# BE-U1000 register map
Vendor: BAIKAL ELECTRONICS, JSC; File version: 1.0
CPU: RISC-V r0p0, little endian, no MPU, no FPU, 3 interrupt priority bits
Registers are 32-bit, read-write, reset 0x0 unless marked. A register's access mark holds for its fields unless they carry their own. Offsets are from the block's base; [hi:lo] are bit positions; {n}, {i} and the like mark numbered series; 'fields as' and 'values as' point back to an identical list; <NAME> marks a mode.

## USB
Base 0x15000000
0x00 FADDR 8-bit — Function address register
  [6:0] FUNC — The function address
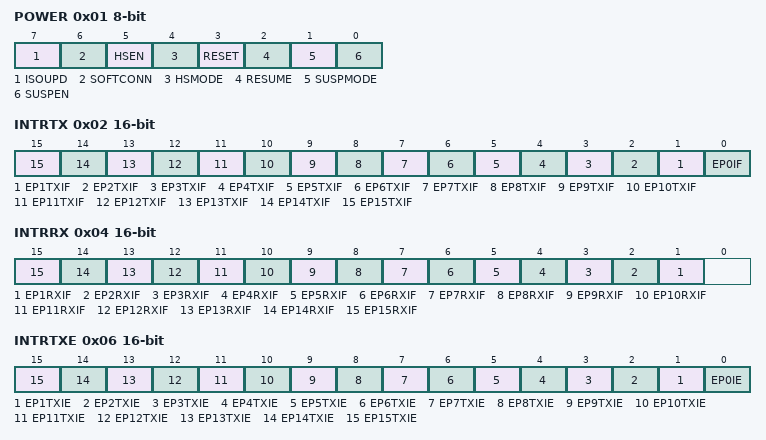
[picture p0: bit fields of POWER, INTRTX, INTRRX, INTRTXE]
0x01 POWER 8-bit — Power management register
  [all] fields
    0=DISABLE; 1=ENABLE
  [7] ISOUPD — ISO Update
  [6] SOFTCONN — Soft Connect/Disconnect feature selection
  [5] HSEN — High-speed mode control
  [4] HSMODE — High-speed mode status
  [3] RESET — Reset status
  [2] RESUME — Resume from Suspend control
  [1] SUSPMODE — Suspend mode status
  [0] SUSPEN — Suspend mode enable
0x02 INTRTX 16-bit — Interrupt register for EP 0 plus EPs 1 to 15
  [all] fields
    0=DISABLE; 1=ENABLE
  [n] EP{n}TXIF (n=1..15) — Endpoint {n} TX Interrupt Flag
  [0] EP0IF — Endpoint 0 Interrupt Flag
0x04 INTRRX 16-bit — Interrupt register for Rx EPs 1 to 15
  [all] fields
    0=DISABLE; 1=ENABLE
  [n] EP{n}RXIF (n=1..15) — Endpoint {n} RX Interrupt Flag
0x06 INTRTXE 16-bit — Interrupt enable register for IntrTx
  [all] fields
    0=DISABLE; 1=ENABLE
  [n] EP{n}TXIE (n=1..15) — Endpoint {n} TX Interrupt Enable
  [0] EP0IE — Endpoint 0 Interrupt Enable
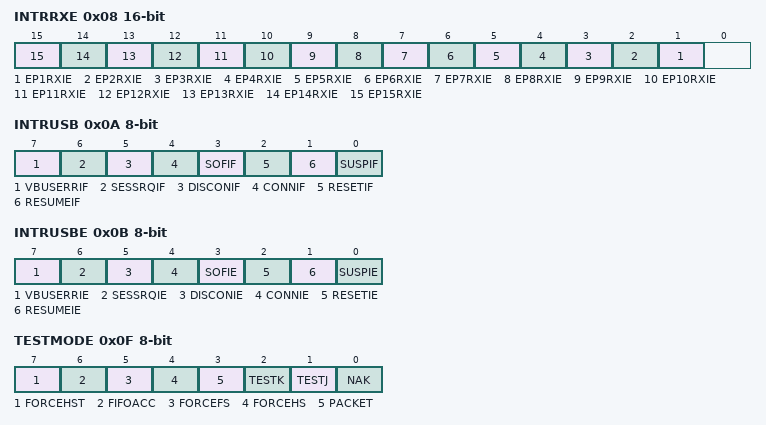
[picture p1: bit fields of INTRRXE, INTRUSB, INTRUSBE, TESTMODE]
0x08 INTRRXE 16-bit — Interrupt enable register for IntrRx
  [all] fields
    0=DISABLE; 1=ENABLE
  [n] EP{n}RXIE (n=1..15) — Endpoint {n} RX Interrupt Enable
0x0A INTRUSB 8-bit — Interrupt register for common USB interrupts
  [all] fields
    0=DISABLE; 1=ENABLE
  [7] VBUSERRIF — VBUS Error Interrupt Flag
  [6] SESSRQIF — Session Request Interrupt Flag
  [5] DISCONIF — Device Disconnect Interrupt Flag
  [4] CONNIF — Device Connection Interrupt Flag
  [3] SOFIF — Start of Frame Interrupt Flag
  [2] RESETIF — Reset/Babble Interrupt Flag
  [1] RESUMEIF — Resume Interrupt Flag
  [0] SUSPIF — Suspend Interrupt Flag
0x0B INTRUSBE 8-bit — Interrupt enable register for IntrUSB
  [all] fields
    0=DISABLE; 1=ENABLE
  [7] VBUSERRIE — VBUS Error Interrupt Enable
  [6] SESSRQIE — Session Request Interrupt Enable
  [5] DISCONIE — Device Disconnect Interrupt Enable
  [4] CONNIE — Device Connection Interrupt Enable
  [3] SOFIE — Start of Frame Interrupt Enable
  [2] RESETIE — Reset/Babble Interrupt Enable
  [1] RESUMEIE — Resume Interrupt Enable
  [0] SUSPIE — Suspend Interrupt Enable
0x0C FRAME 16-bit — Frame number
  [10:0] RFRMNUM — Last received frame number
0x0E INDEX 8-bit — Index register for selecting EP CSR
  [3:0] ENDPOINT — Endpoint registers select
0x0F TESTMODE 8-bit — Enables the USB2.0 test modes
  [all] fields
    0=DISABLE; 1=ENABLE
  [7] FORCEHST — Force host mode select
  [6] FIFOACC — Endpoint 0 FIFO transfer test mode select
  [5] FORCEFS — Force Full-Speed test mode select
  [4] FORCEHS — Force High-Speed test mode select
  [3] PACKET — Test_Packet test mode select
  [2] TESTK — Test_K test mode select
  [1] TESTJ — Test_J test mode select
  [0] NAK — Test_SE0_NAK test mode select
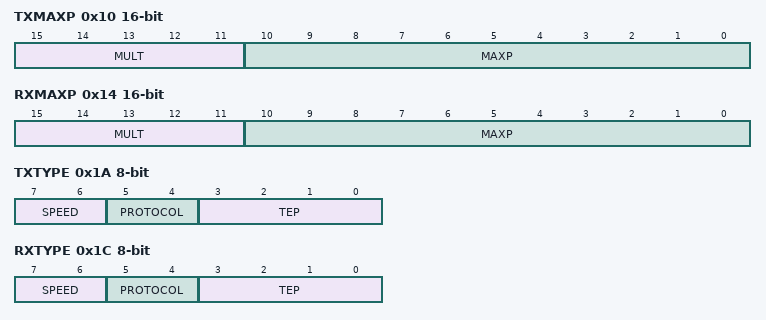
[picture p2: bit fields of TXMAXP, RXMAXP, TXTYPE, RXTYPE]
0x10 TXMAXP 16-bit — Maximum packet size for peripheral Tx EP
  [15:11] MULT — Maximum number of packets into which a single data packet should be split
  [10:0] MAXP — Maximum payload transmitted in a single transaction
0x10 TXMAXP 16-bit — Maximum packet size for host Tx EP
  fields as TXMAXP
0x12 CSR0L 8-bit — Control Status register for EP 0 Low
  [all] fields
    0=DISABLE; 1=ENABLE
  [7] PERIPH_SVSSETEND — Clear SetupEnd bit
  [7] HOST_NAKTMOUT — EP 0 is halted following NAK timeout
  [6] PERIPH_SVCRPR — Clear RxPktRdy bit
  [6] HOST_STATPKT — Perform a status stage transaction
  [5] PERIPH_SENDSTALL — Terminate current transaction
  [5] HOST_REQPKT — IN transaction request
  [4] PERIPH_SETUPEND — Control transaction ended before DataEnd bit has been set
  [4] HOST_ERROR — Three attempts to perform transaction with no response
  [3] PERIPH_DATAEND — TxPktRdy bit set / RxPktRdy bit cleared
  [3] HOST_SETUPPKT — Send SETUP token instead of OUT token
  [2] PERIPH_SENTSTALL — STALL handshake is transmitted
  [2] HOST_RXSTALL — STALL handshake is received
  [1] PERIPH_TXPKTRDY — Data packet loaded into FIFO
  [1] HOST_TXPKTRDY — Data packet loaded into FIFO
  [0] PERIPH_RXPKTRDY — Data packet received
  [0] HOST_RXPKTRDY — Data packet received
0x12 TXCSRL 8-bit — Control Status register for peripheral Tx EP Low
  [all] fields
    0=DISABLE; 1=ENABLE
  [7] PERIPH_INCOMPTX — Insufficient IN tokens for a split large packet
  [7] HOST_INCOMPTX — No response received from the device
  [6] PERIPH_CLRDT — Reset the endpoint data toggle to 0
  [6] HOST_CLRDT — Reset the endpoint data toggle to 0
  [5] PERIPH_SENTSTALL — STALL handshake is transmitted
  [5] HOST_RXSTALL — STALL handshake is received
  [4] PERIPH_SENDSTALL — Issue STALL handshake to IN token
  [4] HOST_SETUPPKT — Send SETUP token instead of OUT token
  [3] PERIPH_FLSHFIFO — Flush the latest packet from the endpoint TX FIFO
  [3] HOST_FLSHFIFO — Flush the latest packet from the endpoint TX FIFO
  [2] PERIPH_UNDERRUN — IN token received when TxPktRdy not set
  [2] HOST_ERROR — Three attempts to send a packet with no handshake received
  [1] PERIPH_FIFONE — At least 1 packet in the TX FIFO
  [1] HOST_FIFONE — At least 1 packet in the TX FIFO
  [0] PERIPH_TXPKTRDY — Data packet loaded into FIFO
  [0] HOST_TXPKTRDY — Data packet loaded into FIFO
0x12 CSR0L 8-bit — Control Status register for EP 0 Low
  fields as CSR0L
0x12 TXCSRL 8-bit — Control Status register for host Tx EP Low
  fields as TXCSRL
0x13 CSR0H 8-bit — Control Status register for EP 0 High
  [all] fields
    0=DISABLE; 1=ENABLE
  [3] HOST_DISPING — Prevent issue of PING tokens in data and status phases
  [2] HOST_DTWREN — Enable EP 0 data toggle state to be written
  [1] HOST_DATATGGL — EP 0 data toggle state
  [0] PERIPH_FLSHFIFO — Flush the next packet from the EP 0 FIFO
  [0] HOST_FLSHFIFO — Flush the next packet from the EP 0 FIFO
0x13 TXCSRH 8-bit — Control Status register for peripheral Tx EP High
  [all] fields
    0=DISABLE; 1=ENABLE
  [7] PERIPH_AUTOSET — Set TxPktRdy bit automatically
  [7] HOST_AUTOSET — Set TxPktRdy bit automatically
  [6] PERIPH_ISO — Set the endpoint transfer type
  [5] PERIPH_MODE — Set the endpoint direction
  [5] HOST_MODE — Set the endpoint direction
  [4] PERIPH_DMAREQEN — Enable the DMA request for the TX endpoint
  [4] HOST_DMAREQEN — Enable the DMA request for the TX endpoint
  [3] PERIPH_FRCDATTG — Force the endpoint data toggle to switch
  [3] HOST_FRCDATTG — Force the endpoint data toggle to switch
  [2] PERIPH_DMAREQMD — Select DMA Request Mode
  [2] HOST_DMAREQMD — Select DMA Request Mode
  [1] HOST_DTWREN — TX endpoint data toggle state write enable
  [0] HOST_DATATGGL — TX endpoint data toggle state
0x13 CSR0H 8-bit — Control Status register for EP 0 High
  fields as CSR0H
0x13 TXCSRH 8-bit — Control Status register for host Tx EP High
  fields as TXCSRH
0x14 RXMAXP 16-bit — Maximum packet size for peripheral Rx EP
  [15:11] MULT — The number of packets to be amalgamated into a single data packet
  [10:0] MAXP — Maximum payload transmitted in a single transaction
0x14 RXMAXP 16-bit — Maximum packet size for host Rx EP
  fields as RXMAXP
0x16 RXCSRL 8-bit — Control Status register for peripheral Rx EP Low
  [all] fields
    0=DISABLE; 1=ENABLE
  [7] PERIPH_CLRDT — Reset the endpoint data toggle to 0
  [7] HOST_CLRDT — Reset the endpoint data toggle to 0
  [6] PERIPH_SENTSTALL — STALL handshake is transmitted
  [6] HOST_RXSTALL — STALL handshake is received
  [5] PERIPH_SENDSTALL — Issue STALL handshake
  [5] HOST_REQPKT — IN transaction request
  [4] PERIPH_FLSHFIFO — Flush the next packet to be read from the EP RX FIFO
  [4] HOST_FLSHFIFO — Flush the next packet to be read from the EP RX FIFO
  [3] PERIPH_DATAERR — Data packet has CRC or bit-stuff error
  [3] HOST_DERRNAKT — CRC or bit-stuff error / NAK timeout
  [2] PERIPH_OVERRUN — OUT packet cannot be loaded into the RX FIFO
  [2] HOST_ERROR — No data packet has been received after three attempts
  [1] PERIPH_FIFOFULL — No more packets can be loaded into the RX FIFO
  [1] HOST_FIFOFULL — No more packets can be loaded into the RX FIFO
  [0] PERIPH_RXPKTRDY — Data packet has been received
  [0] HOST_RXPKTRDY — Data packet has been received
0x16 RXCSRL 8-bit — Control Status register for host Rx EP Low
  fields as RXCSRL
0x17 RXCSRH 8-bit — Control Status register for peripheral Rx EP High
  [all] fields
    0=DISABLE; 1=ENABLE
  [7] PERIPH_AUTOCLR — Clear RxPktRdy bit automatically
  [7] HOST_AUTOCLR — Clear RxPktRdy bit automatically
  [6] PERIPH_ISO — Set the endpoint transfer type
  [6] HOST_AUTOREQ — Set ReqPkt bit automatically
  [5] PERIPH_DMAREQEN — Enable DMA request for the RX endpoint
  [5] HOST_DMAREQEN — Enable DMA request for the RX endpoint
  [4] PERIPH_DISNYET — Disable sending of NYET handshakes
  [4] HOST_PIDERR — PID error in the received packet
  [3] PERIPH_DMAREQMD — Select DMA Request Mode
  [3] HOST_DMAREQMD — Select DMA Request Mode
  [2] HOST_DATATWEN — Enable state of the EP 0 data toggle to be written
  [1] HOST_DATATGGL — State of the EP 0 data toggle
  [0] PERIPH_INCOMPRX — The packet in RX FIFO is incomplete
  [0] HOST_INCOMPRX — The packet received is incomplete
0x17 RXCSRH 8-bit — Control Status register for host Rx EP High
  fields as RXCSRH
0x18 COUNT0 8-bit — Number of received bytes in EP 0 FIFO
  [6:0] EP0RXCNT — The number of received data bytes in the EP 0 FIFO
0x18 RXCOUNT 16-bit — Number of bytes to be read from peripheral Rx EP FIFO
  [13:0] EPRXCNT — The number of data bytes to be read from RX FIFO
0x18 COUNT0 8-bit — Number of received bytes in EP 0 FIFO
  [6:0] EP0RXCNT — The number of received data bytes in the EP 0 FIFO
0x18 RXCOUNT 16-bit — Number of bytes to be read from host Rx EP FIFO
  [13:0] EPRXCNT — The number of data bytes to be read from RX FIFO
0x1A TYPE0 8-bit — Defines the speed of EP 0
  [7:6] SPEED — The operating speed of the targeted device
0x1A TXTYPE 8-bit — Sets protocol, speed and peripheral EP number for the host Tx EP
  [7:6] SPEED — The operating speed of the target device
  [5:4] PROTOCOL — Protocol for the TX endpoint
  [3:0] TEP — EP number from the TX EP descriptor returned during enumeration
0x1B NAKLIMIT0 8-bit — Sets NAK response timeout on EP 0
  [4:0] EP0NAKLIM — The number of NAK responses received for the EP 0 to timeout
0x1B TXINTERVAL 8-bit — Sets polling interval or NAK response timeout for host Tx EP
  [7:0] TXINTERV — Polling interval for TX endpoint
0x1C RXTYPE 8-bit — Sets protocol, speed and peripheral EP number for the host Rx EP
  [7:6] SPEED — The operating speed of the target device
  [5:4] PROTOCOL — Protocol for the RX endpoint
  [3:0] TEP — EP number from the RX EP descriptor returned during enumeration
0x1D RXINTERVAL 8-bit — Sets polling interval or NAK response timeout for host Rx EP
  [7:0] RXINTERV — Polling interval for RX endpoint
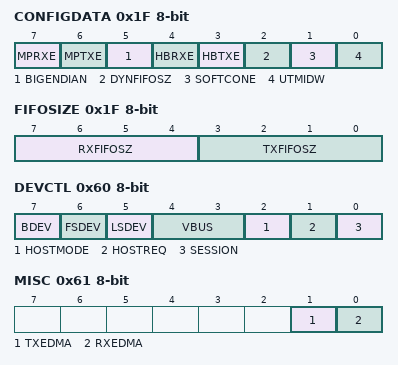
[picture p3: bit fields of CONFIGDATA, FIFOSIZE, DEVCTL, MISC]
0x1F CONFIGDATA 8-bit — Returns details of core configuration
  [all] fields
    0=DISABLE; 1=ENABLE
  [7] MPRXE — Automatic amalgamation of bulk packets
  [6] MPTXE — Automatic splitting of bulk packets
  [5] BIGENDIAN — Indicates Little Endian ordering. Always 0.
  [4] HBRXE — High-bandwidth RX ISO Endpoint Support
  [3] HBTXE — High-bandwidth TX ISO Endpoint Support
  [2] DYNFIFOSZ — Dynamic FIFO Sizing option
  [1] SOFTCONE — Soft Connect/Disconnect
  [0] UTMIDW — UTMI data width
0x1F FIFOSIZE 8-bit — Returns the configured size of the selected Rx FIFO and Tx FIFOs
  [7:4] RXFIFOSZ — RX endpoint FIFO size
  [3:0] TXFIFOSZ — TX endpoint FIFO size
0x1F CONFIGDATA 8-bit — Returns details of core configuration
  fields as CONFIGDATA
0x1F FIFOSIZE 8-bit — Returns the configured size of the selected Rx FIFO and Tx FIFOs
  fields as FIFOSIZE
{0x20+4i} FIFO[{i}] (i=0..15)
0x60 DEVCTL 8-bit — OTG device control register
  [7] BDEV — A device or B device indication
    0=DISABLE; 1=ENABLE
  [6] FSDEV — Full-speed or high-speed device detected
    0=DISABLE; 1=ENABLE
  [5] LSDEV — Low-speed device detected
    0=DISABLE; 1=ENABLE
  [4:3] VBUS — VBus level
    0=LEV0 (Below SessionEnd); 1=LEV1 (Above SessionEnd, below AValid); 2=LEV2 (Above AValid, below VBusValid); 3=LEV3 (Above VBusValid)
  [2] HOSTMODE — Host Mode indication
    0=DISABLE; 1=ENABLE
  [1] HOSTREQ — Initiate Host Negotiation
    0=DISABLE; 1=ENABLE
  [0] SESSION — Start/End of session
    0=DISABLE; 1=ENABLE
0x61 MISC 8-bit — Miscellanious register
  [1] TXEDMA — DMA_REQ signal mode for IN endpoints
    0=DISABLE; 1=ENABLE
  [0] RXEDMA — DMA_REQ signal mode for OUT endpoints
    0=DISABLE; 1=ENABLE
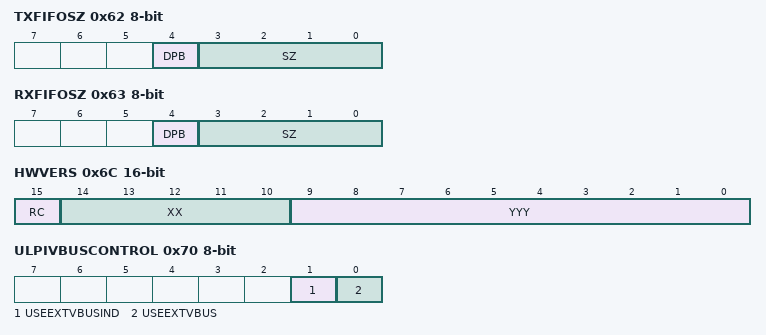
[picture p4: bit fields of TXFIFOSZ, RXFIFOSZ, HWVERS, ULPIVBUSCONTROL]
0x62 TXFIFOSZ 8-bit — Tx EP FIFO size
  [4] DPB — Double-packet buffering support
    0=DISABLE; 1=ENABLE
  [3:0] SZ — The size of the selected TX EP FIFO
    0=8BYTES; 1=16BYTES; 2=32BYTES; 3=64BYTES; 4=128BYTES; 5=256BYTES; 6=512BYTES; 7=1024BYTES; 8=2048BYTES; 9=4096BYTES
0x63 RXFIFOSZ 8-bit — Rx EP FIFO size
  [4] DPB — Double-packet buffering support
    0=DISABLE; 1=ENABLE
  [3:0] SZ — The size of the selected RX EP FIFO
    values as TXFIFOSZ.SZ
0x64 TXFIFOADD 16-bit — Tx EP FIFO address
  [12:0] AD — The start address of the selected TX EP FIFO
0x66 RXFIFOADD 16-bit — Rx EP FIFO address
  [12:0] AD — The start address of the selected RX EP FIFO
0x68 VCONTROL — UTMI + PHY vendor registers
0x68 VSTATUS — UTMI + PHY vendor registers
0x6C HWVERS 16-bit — Hardware version number register
  [15] RC — Release Candidate flag
    0=DISABLE; 1=ENABLE
  [14:10] XX — Major Version Number (Range 0-31)
  [9:0] YYY — Minor Version Number (Range 0-999)
0x70 ULPIVBUSCONTROL 8-bit — VBus control
  [1] USEEXTVBUSIND — The use of an external VBus indicator
    0=DISABLE; 1=ENABLE
  [0] USEEXTVBUS — The use of an external charghe pump
    0=DISABLE; 1=ENABLE
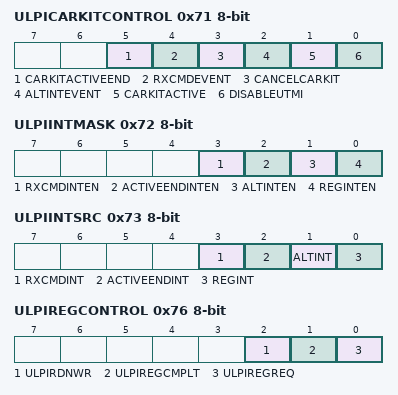
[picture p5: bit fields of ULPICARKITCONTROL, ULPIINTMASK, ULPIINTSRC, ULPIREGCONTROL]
0x71 ULPICARKITCONTROL 8-bit — CarKit system control
  [all] fields
    0=DISABLE; 1=ENABLE
  [5] CARKITACTIVEEND — CarKitActive is cleared
  [4] RXCMDEVENT — A RxCmd has been latched
  [3] CANCELCARKIT — An alt_int event occured
  [2] ALTINTEVENT — An alt_int event occured
  [1] CARKITACTIVE — The CarKit mode is entered after DIR goes high
  [0] DISABLEUTMI — Decouple the reconstituted UTMI signals from the USB controller prior to entering CarKit mode
0x72 ULPIINTMASK 8-bit — Interrupt enable
  [all] fields
    0=DISABLE; 1=ENABLE
  [3] RXCMDINTEN — Assert MC_NINT if ULPIIntSrc.RxCmdInt is set
  [2] ACTIVEENDINTEN — Assert MC_NINT if ULPIIntSrc.ActiveEndInt is set
  [1] ALTINTEN — Assert MC_NINT if ULPIIntSrc.AltInt is set
  [0] REGINTEN — Assert MC_NINT if ULPIIntSrc.RegInt is set
0x73 ULPIINTSRC 8-bit — Interrupt source
  [all] fields
    0=DISABLE; 1=ENABLE
  [3] RXCMDINT — Asserted if ULPICarKitControl.RxCmdEvent is set
  [2] ACTIVEENDINT — Asserted if ULPICarKitControl.CarKitActiveEnd is set
  [1] ALTINT — Asserted if ULPICarKitControl.AltIntEvent is set
  [0] REGINT — Asserted if ULPIRegControl.ULPIRegCmplt is set
0x74 ULPIREGDATA 8-bit — Data associated with register read/writes
0x75 ULPIREGADDR 8-bit — Address of the register being read/written
0x76 ULPIREGCONTROL 8-bit — Control and status bits
  [all] fields
    0=DISABLE; 1=ENABLE
  [2] ULPIRDNWR — Register read/write access
  [1] ULPIREGCMPLT — Register access is complete
  [0] ULPIREGREQ — Initiate register access
0x77 ULPIRAWDATA 8-bit — Asynchronous and synchronous mode data
  [7] SYNC_ALT_INT — A non-USB interrupt occured
    0=DISABLE; 1=ENABLE
  [6] SYNC_ID — The value of the IDDIG (valid 50ms after IDPULLUP is asserted)
    0=DISABLE; 1=ENABLE
  [5:4] SYNC_RXEVENT — Encoded UTMI event signals
  [3] ASYNC_DATA3 — Active high interrupt indication (int)
    0=DISABLE; 1=ENABLE
  [2] ASYNC_DATA2 — Single-ended zero (se0)
    0=DISABLE; 1=ENABLE
  [3:2] SYNC_VBUSSTATE — VBus voltage state
    0=USB_ULPIRAWDATA_SYNC_VBUSSTATE0 (VBus < VB_Sess_END); 1=USB_ULPIRAWDATA_SYNC_VBUSSTATE1 (VB_Sess_END <= VBus < V_Sess_VLD); 2=USB_ULPIRAWDATA_SYNC_VBUSSTATE2 (V_Sess_VLD <= VBus < VA_VBus_VLD); 3=USB_ULPIRAWDATA_SYNC_VBUSSTATE3 (VA_VBus_VLD < VBus)
  [1] ASYNC_DATA1 — Differential data (dat)
    0=DISABLE; 1=ENABLE
  [0] ASYNC_DATA0 — Active high transmit enable (tx_enable)
    0=DISABLE; 1=ENABLE
  [1:0] SYNC_LINESTATE — UTMI+ LineState signals
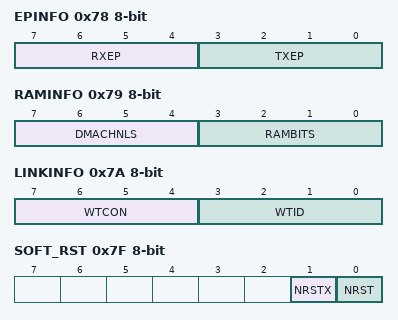
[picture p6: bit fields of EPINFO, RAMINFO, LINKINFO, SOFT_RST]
0x78 EPINFO 8-bit — Numbers of Tx and Rx EPs
  [7:4] RXEP — The number of RX endpoints implemented
  [3:0] TXEP — The number of TX endpoints implemented
0x79 RAMINFO 8-bit — The width of RAM and the number of DMA channels
  [7:4] DMACHNLS — The number of DMA channels implemented
  [3:0] RAMBITS — The width of the RAM address bus
0x7A LINKINFO 8-bit — Delays to be applied
  [7:4] WTCON — The delay to allow for user's connect/disconnect filter
  [3:0] WTID — The delay from IDPULLUP asserted to IDDIG considered valid
0x7B VPLEN 8-bit — Duration of the VBus pulsing charge
0x7C HS_EOF1 8-bit — Time buffer available on HS transactions
0x7D FS_EOF1 8-bit — Time buffer available on FS transactions
0x7E LS_EOF1 8-bit — Time buffer available on LS transactions
0x7F SOFT_RST 8-bit — Soft reset
  [1] NRSTX — NRSTOX signal control
    0=DISABLE; 1=ENABLE
  [0] NRST — NRSTO signal control
    0=DISABLE; 1=ENABLE
{0x80+8i} TXFUNCADDR{i} 8-bit (i=0..15) — Tx EP {i} function address (Host mode only)
  [6:0] ADDR — The address of the target function
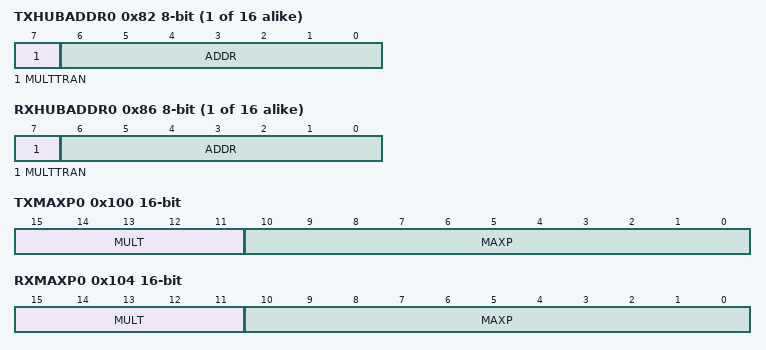
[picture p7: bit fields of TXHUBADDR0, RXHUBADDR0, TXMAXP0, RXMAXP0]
{0x82+8i} TXHUBADDR{i} 8-bit (i=0..15) — Tx EP {i} hub address (Host mode only)
  [7] MULTTRAN — Hub multiple transaction translators flag
    0=DISABLE; 1=ENABLE
  [6:0] ADDR — The address of the USB hub
{0x83+8i} TXHUBPORT{i} 8-bit (i=0..15) — Tx EP {i} hub port (Host mode only)
  [6:0] PORT — The port of the USB hub
{0x84+8i} RXFUNCADDR{i} 8-bit (i=0..15) — Rx EP {i} function address (Host mode only)
  [6:0] ADDR — The address of the target function
{0x86+8i} RXHUBADDR{i} 8-bit (i=0..15) — Rx EP {i} hub address (Host mode only)
  fields as TXHUBADDR0
{0x87+8i} RXHUBPORT{i} 8-bit (i=0..15) — Rx EP {i} hub port (Host mode only)
  [6:0] PORT — The port of the USB hub
0x100 TXMAXP0 16-bit — Maximum packet size for peripheral Tx EP 0
  fields as TXMAXP
0x100 TXMAXP0 16-bit — Maximum packet size for host Tx EP 0
  fields as TXMAXP
0x102 CSR0L0 8-bit — Control Status register for EP 0 Low
  fields as CSR0L
0x102 TXCSRL0 8-bit — Control Status register for peripheral Tx EP 0 Low
  fields as TXCSRL
0x102 CSR0L0 8-bit — Control Status register for EP 0 Low
  fields as CSR0L
0x102 TXCSRL0 8-bit — Control Status register for host Tx EP 0 Low
  fields as TXCSRL
0x103 CSR0H0 8-bit — Control Status register for EP 0 High
  fields as CSR0H
0x103 TXCSRH0 8-bit — Control Status register for peripheral Tx EP 0 High
  fields as TXCSRH
0x103 CSR0H0 8-bit — Control Status register for EP 0 High
  fields as CSR0H
0x103 TXCSRH0 8-bit — Control Status register for host Tx EP 0 High
  fields as TXCSRH
0x104 RXMAXP0 16-bit — Maximum packet size for peripheral Rx EP 0
  fields as RXMAXP
0x104 RXMAXP0 16-bit — Maximum packet size for host Rx EP 0
  fields as RXMAXP
0x106 RXCSRL0 8-bit — Control Status register for peripheral Rx EP 0 Low
  fields as RXCSRL
0x106 RXCSRL0 8-bit — Control Status register for host Rx EP 0 Low
  fields as RXCSRL
0x107 RXCSRH0 8-bit — Control Status register for peripheral Rx EP 0 High
  fields as RXCSRH
0x107 RXCSRH0 8-bit — Control Status register for host Rx EP 0 High
  fields as RXCSRH
0x108 COUNT00 8-bit — Number of received bytes in EP 0 FIFO
  [6:0] EP0RXCNT — The number of received data bytes in the EP 0 FIFO
0x108 RXCOUNT0 16-bit — Number of bytes to be read from peripheral Rx EP 0 FIFO
  [13:0] EPRXCNT — The number of data bytes to be read from RX FIFO
0x108 COUNT00 8-bit — Number of received bytes in EP 0 FIFO
  [6:0] EP0RXCNT — The number of received data bytes in the EP 0 FIFO
0x108 RXCOUNT0 16-bit — Number of bytes to be read from host Rx EP 0 FIFO
  [13:0] EPRXCNT — The number of data bytes to be read from RX FIFO
0x10A TYPE00 8-bit — Defines the speed of EP 0
  [7:6] SPEED — The operating speed of the targeted device
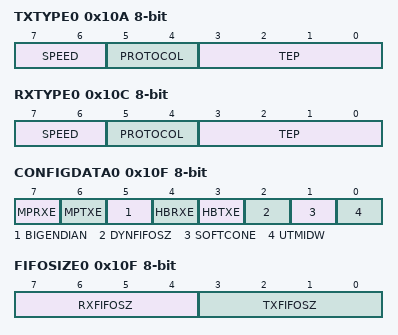
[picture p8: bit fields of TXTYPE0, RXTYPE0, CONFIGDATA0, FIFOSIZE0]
0x10A TXTYPE0 8-bit — Sets protocol, speed and peripheral EP number for the host Tx EP 0
  fields as TXTYPE
0x10B NAKLIMIT00 8-bit — Sets NAK response timeout on EP 0
  fields as NAKLIMIT0
0x10B TXINTERVAL0 8-bit — Sets polling interval or NAK response timeout for host Tx EP 0
  [7:0] TXINTERV — Polling interval for TX endpoint
0x10C RXTYPE0 8-bit — Sets protocol, speed and peripheral EP number for the host Rx EP 0
  fields as RXTYPE
0x10D RXINTERVAL0 8-bit — Sets polling interval or NAK response timeout for host Rx EP 0
  [7:0] RXINTERV — Polling interval for RX endpoint
0x10F CONFIGDATA0 8-bit — Returns details of core configuration 0
  fields as CONFIGDATA
0x10F FIFOSIZE0 8-bit — Returns the configured size of the selected Rx FIFO and Tx FIFOs 0
  fields as FIFOSIZE
0x10F CONFIGDATA0 8-bit — Returns details of core configuration 0
  fields as CONFIGDATA
0x10F FIFOSIZE0 8-bit — Returns the configured size of the selected Rx FIFO and Tx FIFOs0
  fields as FIFOSIZE
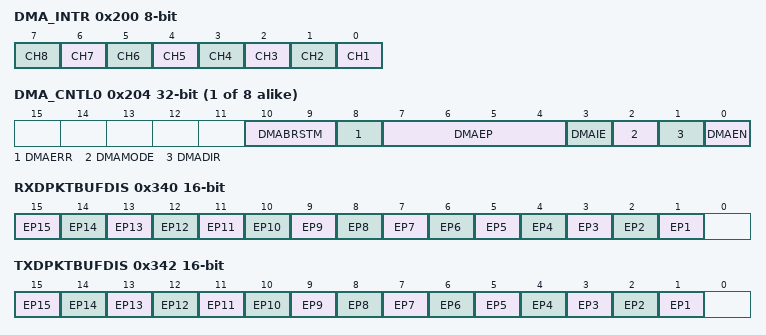
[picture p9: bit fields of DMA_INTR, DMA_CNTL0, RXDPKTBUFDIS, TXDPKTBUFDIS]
0x200 DMA_INTR 8-bit — DMA interrupt register
  [all] fields
    0=DISABLE; 1=ENABLE
  [n-1] CH{n} (n=1..8) — Channel {n} DMA interrupt
{0x204+0x10*i} DMA_CNTL{i} (i=0..7) — DMA control register for channel {i}
  [10:9] DMABRSTM — Burst Mode
    0=MODE0 (Burst Mode 0: Bursts of unspecified length); 1=MODE1 (Burst Mode 1: INCR4 or unspecified length); 2=MODE2 (Burst Mode 2: INCR8, INCR4 or unspecified length); 3=MODE3 (Burst Mode 3: INCR16, INCR8, INCR4 or unspecified length)
  [8] DMAERR — Bus Error Bit
    0=DISABLE; 1=ENABLE
  [7:4] DMAEP — The endpoint number the channel is assigned to
    {v}=EP{v} (Endpoint {v}) (v=0..15)
  [3] DMAIE — DMA interrupt enable
    0=DISABLE (DMA interrupt disabled); 1=ENABLE (DMA interrupt enabled)
  [2] DMAMODE — DMA transfer mode
    0=MODE0 (DMA Mode0 Transfer); 1=MODE1 (DMA Mode1 Transfer)
  [1] DMADIR — DMA transfer direction
    0=WRITE (DMA Write (RX Endpoint)); 1=READ (DMA Read (TX Endpoint))
  [0] DMAEN — DMA transfer enable
    0=DISABLE (DMA transfer disabled); 1=ENABLE (DMA transfer enabled)
{0x208+0x10*i} DMA_ADDR{i} (i=0..7) — DMA address register for channel {i}
{0x20C+0x10*i} DMA_COUNT{i} (i=0..7) — DMA count register for channel {i}
{0x300+4i} EP{i}_RQPKTCOUNT 16-bit (i=1..15) — Number of requested packets for Rx EP {i}
0x340 RXDPKTBUFDIS 16-bit — Double Packet Buffer Disable register for Rx EPs 1 to 15
  [all] fields
    0=DISABLE; 1=ENABLE
  [n] EP{n} (n=1..15) — Rx Double Packet Buffer Disable for EP {n}
0x342 TXDPKTBUFDIS 16-bit — Double Packet Buffer Disable register for Tx EPs 1 to 15
  [all] fields
    0=DISABLE; 1=ENABLE
  [n] EP{n} (n=1..15) — Tx Double Packet Buffer Disable for EP {n}
0x344 C_T_UCH 16-bit — Chirp Timeout Timer
0x346 C_T_HSRTN 16-bit — Delay from the end of HS resume signal
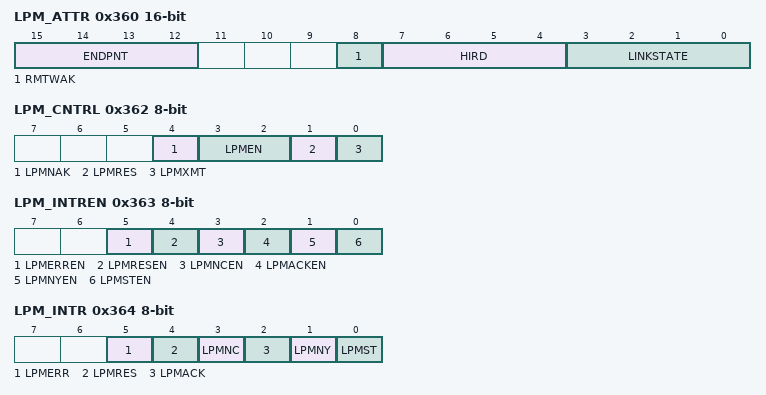
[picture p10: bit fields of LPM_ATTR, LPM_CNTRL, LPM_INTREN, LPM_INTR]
0x360 LPM_ATTR 16-bit — LPM Attribute register
  [15:12] ENDPNT — EP in the Token Packet of the LPM transaction
  [8] RMTWAK — Remote wakeup enable
    0=DISABLE; 1=ENABLE
  [7:4] HIRD — Host Initiated Resume Duration
  [3:0] LINKSTATE — The state that the peripheral must transit to after LPM transaction
0x362 LPM_CNTRL 8-bit — LPM Control register
  [4] LPMNAK — Peripheral: Set all EPs to response NAK to all transactions except LPM
    0=DISABLE; 1=ENABLE
  [3:2] LPMEN — Peripheral: Enable LPM
  [1] LPMRES — Peripheral: Initiate resume (remote wakeup)
    0=DISABLE; 1=ENABLE
  [0] LPMXMT — Peripheral: Transit to L1 state on receipt of the next LPM transaction
    0=DISABLE; 1=ENABLE
0x363 LPM_INTREN 8-bit — LPM Interrupt Enable register
  [all] fields
    0=DISABLE; 1=ENABLE
  [5] LPMERREN — Enable LPMERR interrupt
  [4] LPMRESEN — Enable LPMRES interrupt
  [3] LPMNCEN — Enable LPMNC interrupt
  [2] LPMACKEN — Enable LPMACK interrupt
  [1] LPMNYEN — Enable LPMNY interrupt
  [0] LPMSTEN — Enable LPMST interrupt
0x364 LPM_INTR 8-bit — LPM Interrupt register
  [all] fields
    0=DISABLE; 1=ENABLE
  [5] LPMERR — Peripheral: LPM transaction received with LinkState field that is not supported
  [4] LPMRES — Peripheral: USB has been resumed for any reason
  [3] LPMNC — Peripheral: LPM transaction received and responded with NYET due to data pending in RX FIFO
  [2] LPMACK — Peripheral: LPM transaction received and responded with ACK
  [1] LPMNY — Peripheral: LPM transaction received and responded with NYET
  [0] LPMST — Peripheral: LPM transaction received and responded with STALL
0x365 LPM_FADDR 8-bit — LPM Function Address register
  [6:0] ADDR — The LPM function address
